VERSION ""

NS_ :

BS_:

BU_: Gateway SCADAS_XS

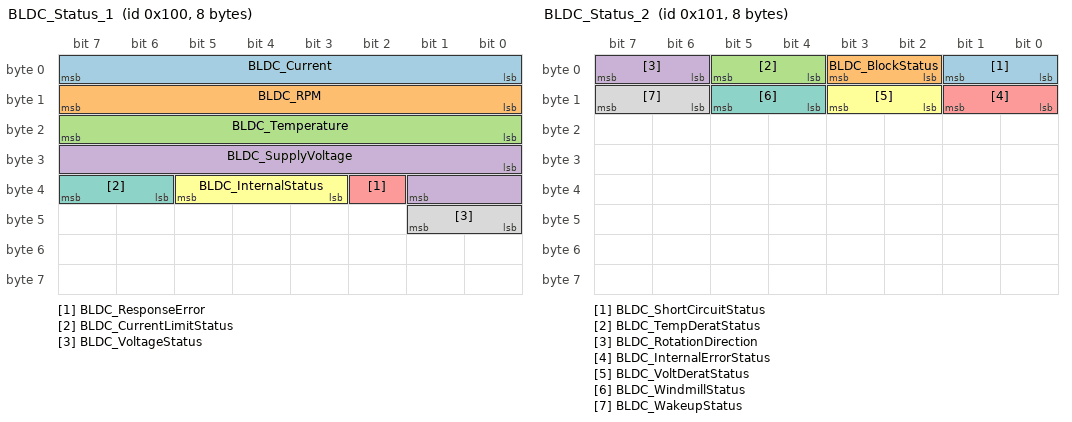
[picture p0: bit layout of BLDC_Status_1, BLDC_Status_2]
BO_ 256 BLDC_Status_1: 8 Gateway
 SG_ BLDC_Current : 0|8@1+ (0.15,0) [0|38.1] "A" SCADAS_XS
 SG_ BLDC_RPM : 8|8@1+ (25,0) [0|6300] "rpm" SCADAS_XS
 SG_ BLDC_Temperature : 16|8@1+ (1,-40) [-40|210] "degC" SCADAS_XS
 SG_ BLDC_SupplyVoltage : 24|10@1+ (0.1,0) [0|102] "V" SCADAS_XS
 SG_ BLDC_ResponseError : 34|1@1+ (1,0) [0|1] "" SCADAS_XS
 SG_ BLDC_InternalStatus : 35|3@1+ (1,0) [0|7] "" SCADAS_XS
 SG_ BLDC_CurrentLimitStatus : 38|2@1+ (1,0) [0|3] "" SCADAS_XS
 SG_ BLDC_VoltageStatus : 40|2@1+ (1,0) [0|3] "" SCADAS_XS

BO_ 257 BLDC_Status_2: 8 Gateway
 SG_ BLDC_ShortCircuitStatus : 0|2@1+ (1,0) [0|3] "" SCADAS_XS
 SG_ BLDC_BlockStatus : 2|2@1+ (1,0) [0|3] "" SCADAS_XS
 SG_ BLDC_TempDeratStatus : 4|2@1+ (1,0) [0|3] "" SCADAS_XS
 SG_ BLDC_RotationDirection : 6|2@1+ (1,0) [0|3] "" SCADAS_XS
 SG_ BLDC_InternalErrorStatus : 8|2@1+ (1,0) [0|3] "" SCADAS_XS
 SG_ BLDC_VoltDeratStatus : 10|2@1+ (1,0) [0|3] "" SCADAS_XS
 SG_ BLDC_WindmillStatus : 12|2@1+ (1,0) [0|3] "" SCADAS_XS
 SG_ BLDC_WakeupStatus : 14|2@1+ (1,0) [0|3] "" SCADAS_XS

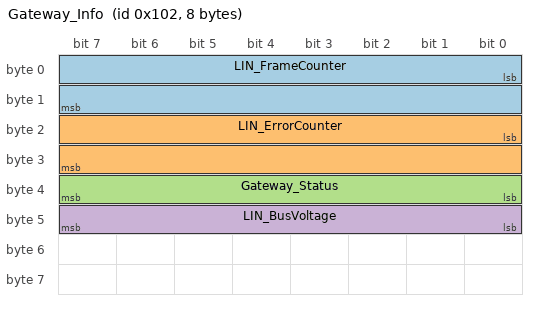
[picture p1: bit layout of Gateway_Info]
BO_ 258 Gateway_Info: 8 Gateway
 SG_ LIN_FrameCounter : 0|16@1+ (1,0) [0|65535] "" SCADAS_XS
 SG_ LIN_ErrorCounter : 16|16@1+ (1,0) [0|65535] "" SCADAS_XS
 SG_ Gateway_Status : 32|8@1+ (1,0) [0|255] "" SCADAS_XS
 SG_ LIN_BusVoltage : 40|8@1+ (0.1,0) [0|25.5] "V" SCADAS_XS

CM_ BU_ Gateway "STM32 CAN-LIN Gateway";
CM_ BU_ SCADAS_XS "Siemens SCADAS XS Data Acquisition System";
CM_ BO_ 256 "BLDC Motor Primary Status (RPM, Current, Temperature, Voltage)";
CM_ BO_ 257 "BLDC Motor Secondary Status (Error and Diagnostic Flags)";
CM_ BO_ 258 "Gateway Health and Statistics";
CM_ SG_ 256 BLDC_Current "Motor current consumption";
CM_ SG_ 256 BLDC_RPM "Motor rotation speed";
CM_ SG_ 256 BLDC_Temperature "Internal PCB temperature";
CM_ SG_ 256 BLDC_SupplyVoltage "Supply voltage to motor controller";
CM_ SG_ 256 BLDC_InternalStatus "Motor operating state";

BA_DEF_ "BusType" STRING ;
BA_DEF_ BO_ "GenMsgCycleTime" INT 0 10000;

BA_DEF_DEF_ "BusType" "CAN";
BA_DEF_DEF_ BO_ "GenMsgCycleTime" 0;

BA_ "GenMsgCycleTime" BO_ 256 20;
BA_ "GenMsgCycleTime" BO_ 257 20;
BA_ "GenMsgCycleTime" BO_ 258 100;

VAL_ 256 BLDC_InternalStatus 0 "SPEED_0" 1 "START_PROC" 2 "RAMPING_UP" 3 "TARGET_SPEED_RCH" 4 "TARGET_SPEED_OUT_OF_RANGE" 5 "DERATING" 6 "STOPPED" 7 "SNA" ;
VAL_ 256 BLDC_CurrentLimitStatus 0 "INACTIVE" 1 "ACTIVE" 2 "TEMP" 3 "SNA" ;
VAL_ 256 BLDC_VoltageStatus 0 "VOLT_RANGE_OK" 1 "UNDERVOLTAGE" 2 "OVERVOLTAGE" 3 "SNA" ;
VAL_ 257 BLDC_ShortCircuitStatus 0 "IDLE" 1 "INACTIVE" 2 "ACTIVE" 3 "SNA" ;
VAL_ 257 BLDC_BlockStatus 0 "IDLE" 1 "INACTIVE" 2 "ACTIVE" 3 "SNA" ;
VAL_ 257 BLDC_TempDeratStatus 0 "TEMP_OK" 1 "TEMP_DERATE" 2 "TEMP_STOP" 3 "SNA" ;
VAL_ 257 BLDC_RotationDirection 0 "IDLE" 1 "CW" 2 "CCW" 3 "SNA" ;
VAL_ 257 BLDC_InternalErrorStatus 0 "IDLE" 1 "NO_ERROR" 2 "ERROR" 3 "SNA" ;
VAL_ 257 BLDC_VoltDeratStatus 0 "IDLE" 1 "NO_DERATE" 2 "DERATE" 3 "SNA" ;
VAL_ 257 BLDC_WindmillStatus 0 "NO_WINDMILL" 1 "AGAINST_ROT_DIR" 2 "IN_ROT_DIR" 3 "SNA" ;
VAL_ 257 BLDC_WakeupStatus 0 "NO_WUP" 1 "ACTIVE_WUP" 2 "NDEF2" 3 "SNA" ;
VAL_ 258 Gateway_Status 0 "INIT" 1 "LIN_READY" 2 "CAN_READY" 3 "RUNNING" 4 "LIN_ERROR" 5 "CAN_ERROR" ;
